# CH32H417 register map
Vendor: WCH Ltd.; File version: 1.2
Registers are 32-bit, read-write, reset 0x0 unless marked. A register's access mark holds for its fields unless they carry their own. Offsets are from the block's base; [hi:lo] are bit positions; {n}, {i} and the like mark numbered series.

## RCC — Reset and clock control
Base 0x40021000
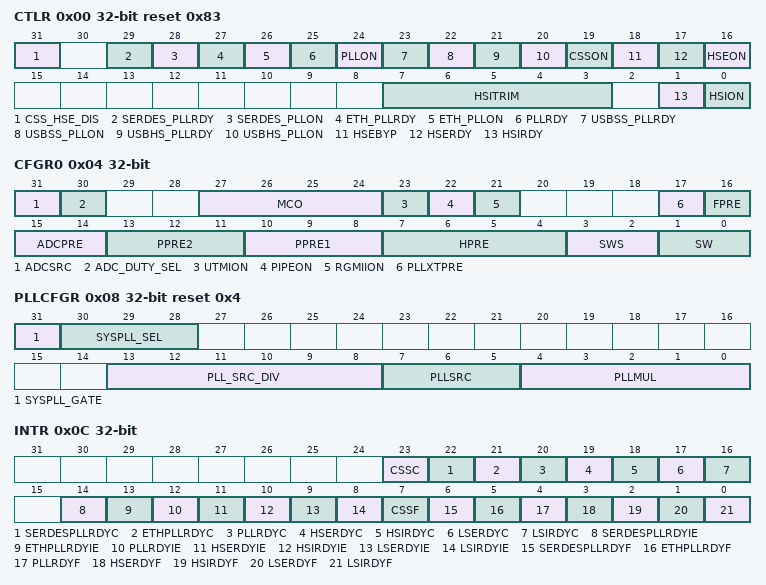
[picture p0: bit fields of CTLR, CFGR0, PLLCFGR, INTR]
0x00 CTLR access per field reset 0x83 — Clock control register
  [31] CSS_HSE_DIS rw — Upon the occurrence of an HSE failure event with CSSON enabled
  [29] SERDES_PLLRDY ro — SERDES PLL clock ready flag
  [28] SERDES_PLLON rw — SERDES PLL clock enable
  [27] ETH_PLLRDY ro — ETH PLL clock ready flag
  [26] ETH_PLLON rw — ETH PLL clock enable
  [25] PLLRDY ro — PLL clock ready flag
  [24] PLLON rw — PLL clock enable
  [23] USBSS_PLLRDY ro — USBSS PLL clock ready flag
  [22] USBSS_PLLON rw — USBSS PLL clock enable
  [21] USBHS_PLLRDY ro — USBHS PLL clock ready flag
  [20] USBHS_PLLON rw — USBHS PLL clock enable
  [19] CSSON rw — Clock Security System enable
  [18] HSEBYP rw — External High Speed clock Bypass
  [17] HSERDY ro — External High Speed clock ready flag
  [16] HSEON rw — External High Speed clock enable
  [7:3] HSITRIM rw — Internal High Speed clock trimming
  [1] HSIRDY ro — Internal High Speed clock ready flag
  [0] HSION rw — Internal High Speed clock enable
0x04 CFGR0 access per field — Clock configuration register (RCC_CFGR0)
  [31] ADCSRC rw — ADC intput clock source selection
  [30] ADC_DUTY_SEL rw — ADC clock duty cycle selection
  [27:24] MCO rw — Microcontroller clock output
  [23] UTMION rw — UTMI clock gating enable
  [22] PIPEON rw — USBSS_PLL clock gating enable
  [21] RGMIION rw — GMII clock gating enable
  [17] PLLXTPRE rw — HSE divider for PLL entry
  [16] FPRE rw — HCLK prescaler
  [15:14] ADCPRE rw — ADC prescaler
  [13:11] PPRE2 rw — TIMER or ADC clock prescaler (PB2)
  [10:8] PPRE1 rw — Timer prescaler (PB1)
  [7:4] HPRE rw — HB prescaler
  [3:2] SWS ro — System Clock Switch Status
  [1:0] SW rw — System clock Switch
0x08 PLLCFGR reset 0x4 — PLL clock configuration register (RCC_PLLCFGR)
  [31] SYSPLL_GATE — Switch the System clock to PLL gate
  [30:28] SYSPLL_SEL — Switch the System clock to PLL selection
  [13:8] PLL_SRC_DIV — PLL intput clock source prescaler
  [7:5] PLLSRC — PLL intput clock source selection
  [4:0] PLLMUL — PLL clock multiplication factor
0x0C INTR access per field — Clock interrupt register (RCC_INTR)
  [23] CSSC wo — Clock security system interrupt clear
  [22] SERDESPLLRDYC wo — SERDES Ready Interrupt Clear
  [21] ETHPLLRDYC wo — ETH PLL Ready Interrupt Clear
  [20] PLLRDYC wo — PLL Ready Interrupt Clear
  [19] HSERDYC wo — HSE Ready Interrupt Clear
  [18] HSIRDYC wo — HSI Ready Interrupt Clear
  [17] LSERDYC wo — LSE Ready Interrupt Clear
  [16] LSIRDYC wo — LSI Ready Interrupt Clear
  [14] SERDESPLLRDYIE rw — SERDESPLL Ready Interrupt Enable
  [13] ETHPLLRDYIE rw — ETHPLL Ready Interrupt Enable
  [12] PLLRDYIE rw — PLL Ready Interrupt Enable
  [11] HSERDYIE rw — HSE Ready Interrupt Enable
  [10] HSIRDYIE rw — HSI Ready Interrupt Enable
  [9] LSERDYIE rw — LSE Ready Interrupt Enable
  [8] LSIRDYIE rw — LSI Ready Interrupt Enable
  [7] CSSF ro — Clock Security System Interrupt flag
  [6] SERDESPLLRDYF ro — SERDES_PLL Ready Interrupt flag
  [5] ETHPLLRDYF ro — ETH Ready Interrupt flag
  [4] PLLRDYF ro — PLL Ready Interrupt flag
  [3] HSERDYF ro — HSE Ready Interrupt flag
  [2] HSIRDYF ro — HSI Ready Interrupt flag
  [1] LSERDYF ro — LSE Ready Interrupt flag
  [0] LSIRDYF ro — LSI Ready Interrupt flag
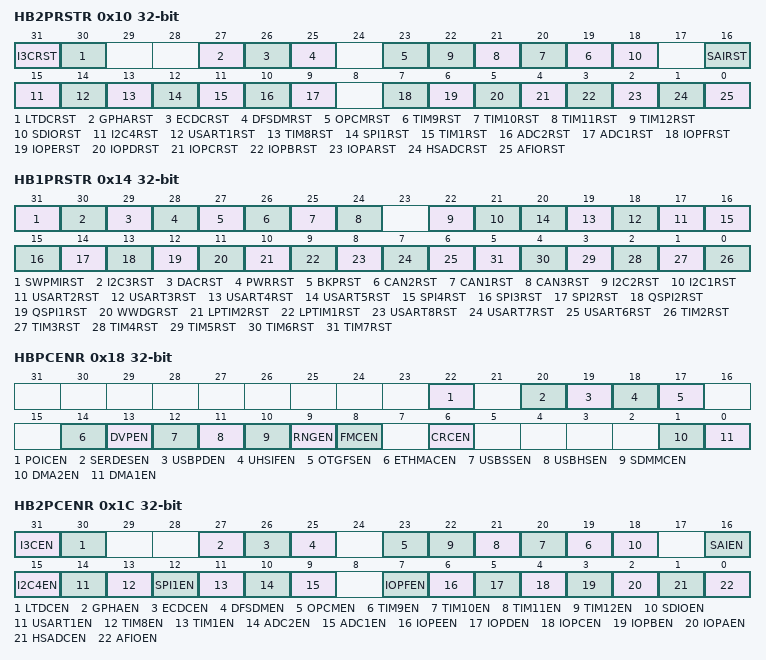
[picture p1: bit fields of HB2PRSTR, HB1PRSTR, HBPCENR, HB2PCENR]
0x10 HB2PRSTR — HB2 peripheral reset register (RCC_HB2PRSTR)
  [31] I3CRST — I3C reset
  [30] LTDCRST — LTDC reset
  [27] GPHARST — GPHA reset
  [26] ECDCRST — ECDC reset
  [25] DFSDMRST — DFSDM reset
  [23] OPCMRST — OPA and CMP reset
  [n+10] TIM{n}RST (n=9..12) — TIM{n} timer reset
  [18] SDIORST — SDIO reset
  [16] SAIRST — SAI reset
  [15] I2C4RST — I2C4 reset
  [14] USART1RST — USART1 reset
  [13] TIM8RST — TIM8 timer reset
  [12] SPI1RST — SPI 1 reset
  [11] TIM1RST — TIM1 timer reset
  [10] ADC2RST — ADC 2 interface reset
  [9] ADC1RST — ADC 1 interface reset
  [7] IOPFRST — IO port F reset
  [6] IOPERST — IO port E reset
  [5] IOPDRST — IO port D reset
  [4] IOPCRST — IO port C reset
  [3] IOPBRST — IO port B reset
  [2] IOPARST — IO port A reset
  [1] HSADCRST — HSADC reset
  [0] AFIORST — Alternate function I/O reset
0x14 HB1PRSTR — HB1 peripheral reset register (RCC_HB1PRSTR)
  [31] SWPMIRST — SWPMI reset
  [30] I2C3RST — I2C3 reset
  [29] DACRST — DAC interface reset
  [28] PWRRST — Power interface reset
  [27] BKPRST — Backup interface reset
  [26] CAN2RST — CAN2 reset
  [25] CAN1RST — CAN1 reset
  [24] CAN3RST — CAN3 reset
  [22] I2C2RST — I2C2 reset
  [21] I2C1RST — I2C1 reset
  [n+15] USART{n}RST (n=2..5) — USART {n} reset
  [16] SPI4RST — SPI4 reset
  [15] SPI3RST — SPI3 reset
  [14] SPI2RST — SPI2 reset
  [13] QSPI2RST — QSPI2 reset
  [12] QSPI1RST — QSPI1 reset
  [11] WWDGRST — Window watchdog reset
  [10] LPTIM2RST — LPTIM2 reset
  [9] LPTIM1RST — LPTIM1 reset
  [8] USART8RST — USART 8 reset
  [7] USART7RST — USART 7 reset
  [6] USART6RST — USART 6 reset
  [n-2] TIM{n}RST (n=2..7) — Timer {n} reset
0x18 HBPCENR — HB Peripheral Clock enable register (RCC_HBPCENR)
  [22] POICEN — POIC clock enable
  [20] SERDESEN — SERDES clock enable
  [19] USBPDEN — USBPD clock enable
  [18] UHSIFEN — UHSIF clock enable
  [17] OTGFSEN — USBFS_OTG_FS clock enable
  [14] ETHMACEN — Ethernet MAC clock enable
  [13] DVPEN — DVP clock enable
  [12] USBSSEN — USBSS clock enable
  [11] USBHSEN — USBHS clock enable
  [10] SDMMCEN — SDMMC clock enable
  [9] RNGEN — RNG clock enable
  [8] FMCEN — FMC clock enable
  [6] CRCEN — CRC clock enable
  [1] DMA2EN — DMA2 clock enable
  [0] DMA1EN — DMA clock enable
0x1C HB2PCENR — HB2 peripheral clock enable register (RCC_HB2PCENR)
  [31] I3CEN — I3C clock enable
  [30] LTDCEN — LTDC clock enable
  [27] GPHAEN — GPHA clock enable
  [26] ECDCEN — ECDC clock enable
  [25] DFSDMEN — DFSDM clock enable
  [23] OPCMEN — OPA and CMP clock enable
  [n+10] TIM{n}EN (n=9..12) — TIM{n} Timer clock enable
  [18] SDIOEN — SDIO clock enable
  [16] SAIEN — SAI clock enable
  [15] I2C4EN — I2C4 clock enable
  [14] USART1EN — USART1 clock enable
  [13] TIM8EN — TIM8 Timer clock enable
  [12] SPI1EN — SPI 1 clock enable
  [11] TIM1EN — TIM1 Timer clock enable
  [10] ADC2EN — ADC 2 interface clock enable
  [9] ADC1EN — ADC1 interface clock enable
  [7] IOPFEN — I/O port F clock enable
  [6] IOPEEN — I/O port E clock enable
  [5] IOPDEN — I/O port D clock enable
  [4] IOPCEN — I/O port C clock enable
  [3] IOPBEN — I/O port B clock enable
  [2] IOPAEN — I/O port A clock enable
  [1] HSADCEN — HSADC clock enable
  [0] AFIOEN — Alternate function I/O clock enable
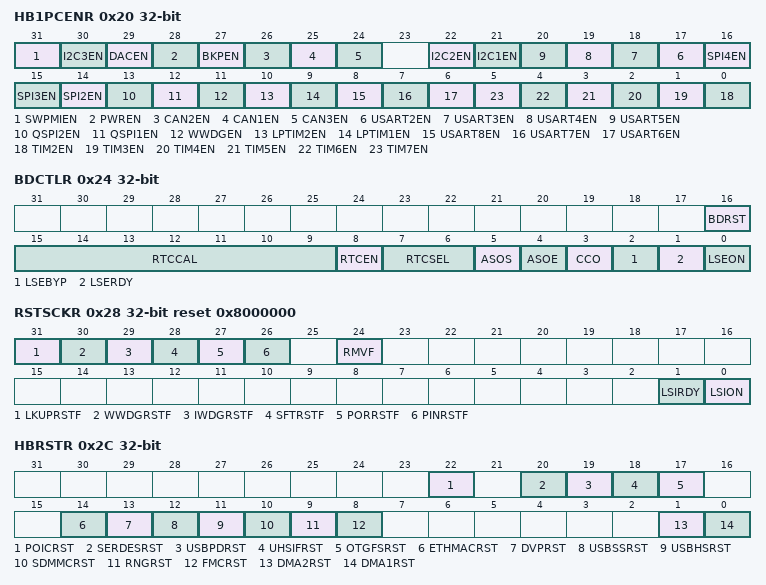
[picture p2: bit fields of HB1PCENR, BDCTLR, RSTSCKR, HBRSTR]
0x20 HB1PCENR — HB1 peripheral clock enable register (RCC_HB1PCENR)
  [31] SWPMIEN — SWPMI clock enable
  [30] I2C3EN — I2C3 clock enable
  [29] DACEN — DAC interface clock enable
  [28] PWREN — Power interface clock enable
  [27] BKPEN — Backup interface clock enable
  [26] CAN2EN — CAN2 clock enable
  [25] CAN1EN — CAN1 clock enable
  [24] CAN3EN — CAN3 clock enable
  [22] I2C2EN — I2C2 clock enable
  [21] I2C1EN — I2C1 clock enable
  [n+15] USART{n}EN (n=2..5) — USART{n} clock enable
  [16] SPI4EN — SPI4 clock enable
  [15] SPI3EN — SPI3 clock enable
  [14] SPI2EN — SPI2 clock enable
  [13] QSPI2EN — QSPI2 clock enable
  [12] QSPI1EN — QSPI1 clock enable
  [11] WWDGEN — Window watchdog clock enable
  [10] LPTIM2EN — LPTIM2 clock enable
  [9] LPTIM1EN — LPTIM1 clock enable
  [8] USART8EN — USART 8 clock enable
  [7] USART7EN — USART 7 clock enable
  [6] USART6EN — USART 6 clock enable
  [n-2] TIM{n}EN (n=2..7) — Timer {n} clock enable
0x24 BDCTLR access per field — Backup domain control register (RCC_BDCTLR)
  [16] BDRST rw — Backup domain software reset
  [15:9] RTCCAL rw — RTC calibration value
  [8] RTCEN rw — RTC clock enable
  [7:6] RTCSEL rw — RTC clock source selection
  [5] ASOS rw — TAMPER pin alarm/second pulse output
  [4] ASOE rw — TAMPER pin enables pulse output
  [3] CCO rw — calibrate the clock output selection
  [2] LSEBYP rw — External Low Speed oscillator bypass
  [1] LSERDY ro — External Low Speed oscillator ready
  [0] LSEON rw — External Low Speed oscillator enable
0x28 RSTSCKR access per field reset 0x8000000 — Control/status register (RCC_RSTSCKR)
  [31] LKUPRSTF rw — LOCKUP reset flag
  [30] WWDGRSTF rw — Window watchdog reset flag
  [29] IWDGRSTF rw — Independent watchdog reset flag
  [28] SFTRSTF rw — Software reset flag
  [27] PORRSTF rw — POR/PDR reset flag
  [26] PINRSTF rw — PIN reset flag
  [24] RMVF rw — Remove reset flag
  [1] LSIRDY ro — Internal low speed oscillator ready
  [0] LSION rw — Internal low speed oscillator enable
0x2C HBRSTR — HB reset register (RCC_PHBRSTR)
  [22] POICRST — POIC reset
  [20] SERDESRST — SERDES reset
  [19] USBPDRST — USBPD reset
  [18] UHSIFRST — UHSIF reset
  [17] OTGFSRST — USBFS_OTG_FS eset
  [14] ETHMACRST — Ethernet MAC reset
  [13] DVPRST — DVP reset
  [12] USBSSRST — USBSS reset
  [11] USBHSRST — USBHS reset
  [10] SDMMCRST — SDMMC reset
  [9] RNGRST — RNG reset
  [8] FMCRST — FMC reset
  [1] DMA2RST — DMA2 reset
  [0] DMA1RST — DMA1 reset
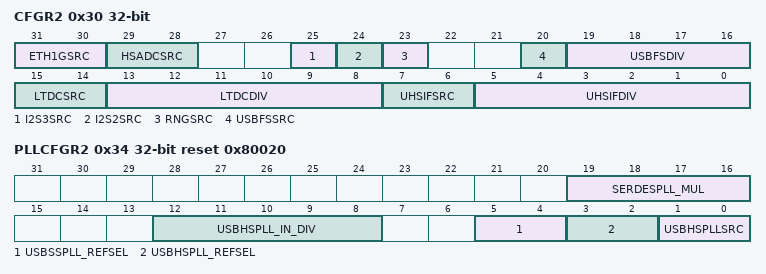
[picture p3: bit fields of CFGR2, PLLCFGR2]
0x30 CFGR2 — Clock configuration register2 (RCC_CFGR2)
  [31:30] ETH1GSRC — ETH1G clock source selection
  [29:28] HSADCSRC — HSADC clock source selection
  [25] I2S3SRC — I2S3 clock source selection
  [24] I2S2SRC — I2S2 clock source selection
  [23] RNGSRC — RNG clock source selection
  [20] USBFSSRC — USBFS 48M clock source selection
  [19:16] USBFSDIV — USBFS 48M division factor
  [15:14] LTDCSRC — LTDC clock source selection
  [13:8] LTDCDIV — LTDC division factor
  [7:6] UHSIFSRC — UHSIF clock source selection
  [5:0] UHSIFDIV — UHSIF division factor
0x34 PLLCFGR2 reset 0x80020 — PLL Clock configuration register2 (RCC_PLLCFGR2)
  [19:16] SERDESPLL_MUL — SERDESPLL clock multiplication factor
  [12:8] USBHSPLL_IN_DIV — USBHS_PLL intput clock source SYS_PLL division setting
  [5:4] USBSSPLL_REFSEL — USBSS_PLL reference clock frequency selection
  [3:2] USBHSPLL_REFSEL — USBHS_PLL reference clock frequency selection
  [1:0] USBHSPLLSRC — USBHS clock source selection
